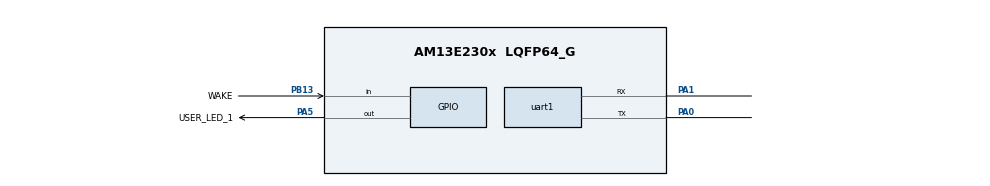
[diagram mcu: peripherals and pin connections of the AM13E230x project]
/**
 * @cliArgs --device "AM13E230x" --part "AM13E230x" --package "LQFP64_G" --product "AM13E2X SDK@26.01.00"
 */
// Port of msp430fr243x_framwrite_persistent: LED4 (red) on PA5, wake button on PB13 (falling edge, interrupt, wake logic), serial port on PA0/PA1.
const gpio   = scripting.addModule("/drivers/gpio", {}, false);
const gpio1  = gpio.addInstance();
const gpio2  = gpio.addInstance();
const uart   = scripting.addModule("/drivers/uart", {}, false);
const uart1  = uart.addInstance();
const sysctl = scripting.addModule("/drivers/sysctl", {}, false);

gpio.registerPort1Interrupt = true;

gpio1.$name                         = "GPIO_LEDS";
gpio1.associatedPins[0].$name       = "USER_LED_1";
gpio1.associatedPins[0].direction   = "OUTPUT";
gpio1.associatedPins[0].pin.$assign = "PA5";

gpio2.$name                         = "GPIO_SWITCH";
gpio2.associatedPins[0].$name       = "WAKE";
gpio2.associatedPins[0].direction   = "INPUT";
gpio2.associatedPins[0].interruptEn = true;
gpio2.associatedPins[0].polarity    = "FALL";
gpio2.associatedPins[0].wakeupLogic = "ON_0";
gpio2.associatedPins[0].fastWakeEn  = true;
gpio2.associatedPins[0].pin.$assign = "PB13";

uart1.$name                    = "APP_UART_0";
uart1.targetBaudRate           = 115200;
uart1.peripheral.rxPin.$assign = "PA1";
uart1.peripheral.txPin.$assign = "PA0";
uart1.txPinConfig.$name        = "drivers_gpio_v0_gpioPinConfig0";
uart1.rxPinConfig.$name        = "drivers_gpio_v0_gpioPinConfig1";

sysctl.peripheral.$suggestSolution = "SYSCTL";
uart1.peripheral.$suggestSolution  = "UC1";
